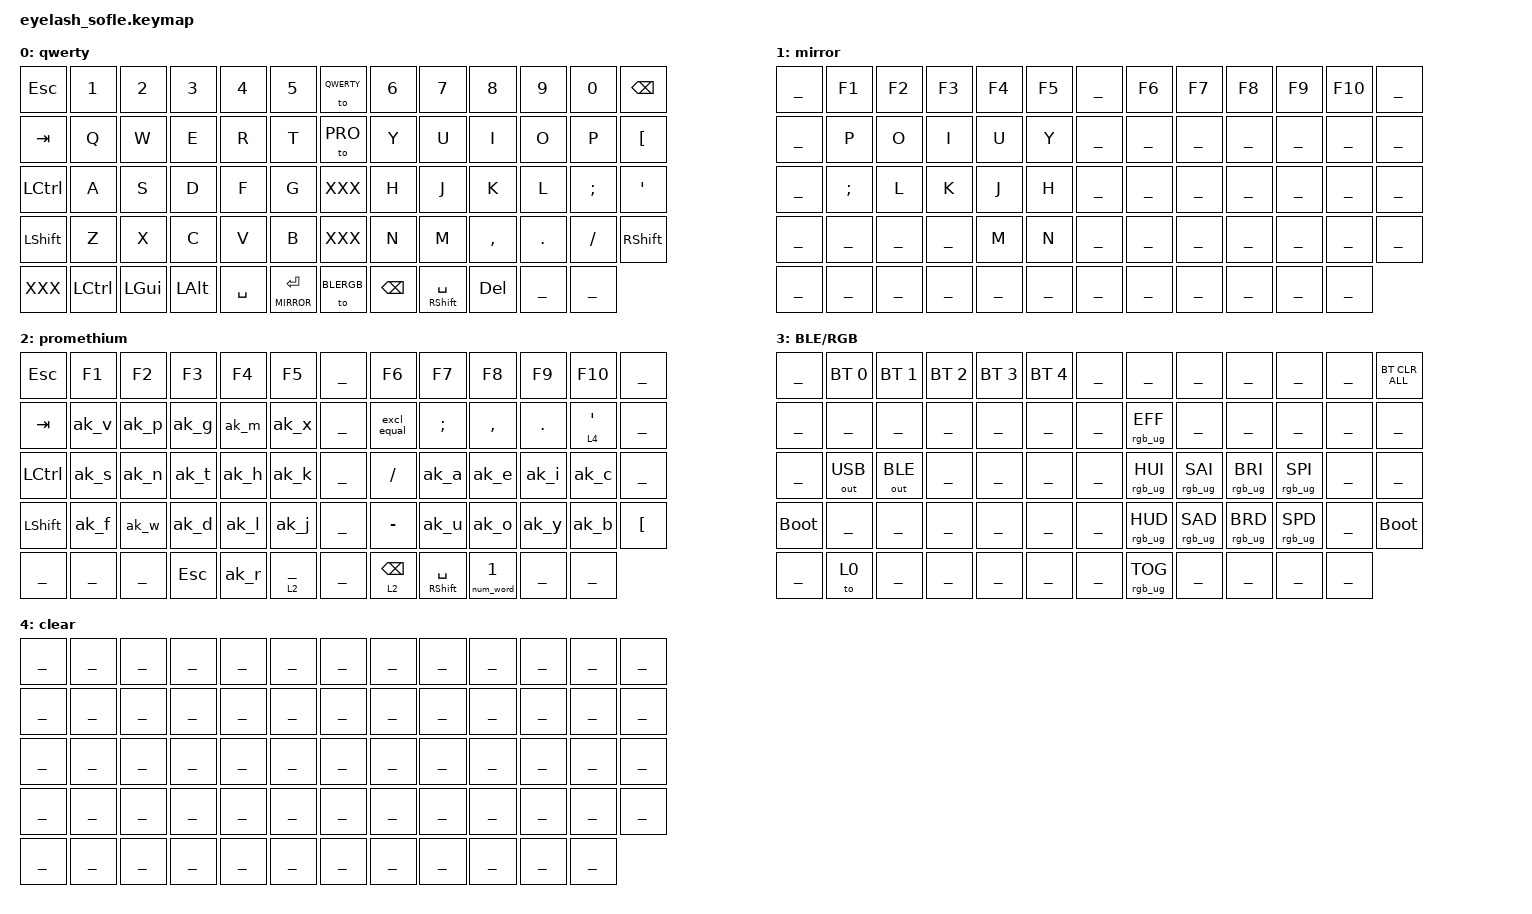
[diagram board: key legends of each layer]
#define ZMK_POINTING_DEFAULT_MOVE_VAL 1200  // 600
#define ZMK_POINTING_DEFAULT_SCRL_VAL 25   // 10

#define LEFT_HAND_KEYS 0 1 2 3 4 5 13 14 15 16 17 18 26 27 28 29 30 31 39 40 41 42 43 44 52 53 54 55 56 57
#define RIGHT_HAND_KEYS 7 8 9 10 11 12 20 21 22 23 24 25 33 34 35 36 37 38 46 47 48 49 50 51 59 60 61 62 63
#define LEFT_LEFT_COLUMN 0 13 26 39
#define THUMBS 52 53 54 55 56 59 60 61 62 63

#define QWERTY 0
#define MIRROR 1
#define PRO 2
#define NAV 0
#define SYM 0
#define FUN 0
#define MISC 0

#include "eyelash_sofle_layout.h"
#include "bernelius/constants.dtsi"

#include <input/processors.dtsi>
#include <zephyr/dt-bindings/input/input-event-codes.h>
#include <behaviors.dtsi>
#include <dt-bindings/zmk/behaviors.h>
#include <dt-bindings/zmk/bt.h>
#include <dt-bindings/zmk/ext_power.h>
#include <dt-bindings/zmk/keys.h>
#include <dt-bindings/zmk/pointing.h>
#include <dt-bindings/zmk/rgb.h>
#include <dt-bindings/zmk/outputs.h>
#include <behaviors/num_word.dtsi>
/*

&mmv_input_listener { input-processors = <&zip_xy_scaler 2 1>; };

&msc_input_listener { input-processors = <&zip_scroll_scaler 2 1>; };

&msc {
    acceleration-exponent = <1>;      // 0
    time-to-max-speed-ms = <100>;       // 300
    delay-ms = <0>;                   // 0
};

&mmv {
    time-to-max-speed-ms = <500>;
    acceleration-exponent = <1>;
    trigger-period-ms = <16>;
};

*/
/ {
    behaviors {
      #include "bernelius/pm_adaptive_keys.dtsi"
      #include "bernelius/behaviors.dtsi"
    };

    combos {
      #include "bernelius/combos.dtsi"
    };

    macros {
        #include "bernelius/macros.dtsi"
    };

    //left-most key on lower row is for an encoder (not currently present on board)


    #define QWERTY 0
    #define MIRROR 1
    #define BLERGB 3
    keymap {
        compatible = "zmk,keymap";

       

        layer_0 {
            display-name = "qwerty";
            bindings = <
//╭───────────────┬───────────────┬───────────────┬───────────────┬────────────────┬───────────────╮                   ╭────────────────┬───────────────┬───────────────┬───────────────┬───────────────┬───────────────╮
   &kp ESC         &kp N1          &kp N2          &kp N3          &kp N4           &kp N5            &to QWERTY        &kp N6           &kp N7          &kp N8          &kp N9          &kp N0          &kp BACKSPACE
//├───────────────┼───────────────┼───────────────┼───────────────┼────────────────┼───────────────┤                   ├────────────────┼───────────────┼───────────────┼───────────────┼───────────────┼───────────────┤
   &kp TAB         &kp Q           &kp W           &kp E           &kp R            &kp T             &to PRO           &kp Y            &kp U           &kp I           &kp O           &kp P           &kp LBKT
//├───────────────┼───────────────┼───────────────┼───────────────┼────────────────┼───────────────┤                   ├────────────────┼───────────────┼───────────────┼───────────────┼───────────────┼───────────────┤
   &kp LCTRL       &kp A           &kp S           &kp D           &kp F            &kp G             XXX               &kp H            &kp J           &kp K           &kp L           &kp SEMI        &kp APOS
//├───────────────┼───────────────┼───────────────┼───────────────┼────────────────┼───────────────┤                   ├────────────────┼───────────────┼───────────────┼───────────────┼───────────────┼───────────────┤ 
   &kp LSHFT       &kp Z           &kp X           &kp C           &kp V            &kp B             XXX               &kp N            &kp M           &kp COMMA       &kp DOT         &kp SLASH       &kp RSHIFT
//╰───────────────┼───────────────┼───────────────┼───────────────┼────────────────┼───────────────┤                   ├────────────────┼───────────────┼───────────────┼───────────────┼───────────────┼───────────────╯ 
   XXX             &kp LCTRL       &kp LGUI        &kp LALT        &kp SPACE        &lt MIRROR ENTER  &to BLERGB        &kp BACKSPACE    &mt RSHIFT SPACE &kp DELETE      ___             ___   
//                ╰───────────────┴───────────────┴───────────────┴────────────────┴───────────────╯                   ╰────────────────┴───────────────┴───────────────┴───────────────┴───────────────╯
            >;
        };

         layer_1 {
            display-name = "mirror";
            bindings = <
//╭───────────────┬───────────────┬───────────────┬───────────────┬───────────────┬───────────────╮                   ╭───────────────┬───────────────┬───────────────┬───────────────┬───────────────┬───────────────╮
   ___             &kp F1          &kp F2          &kp F3          &kp F4          &kp F5            ___ /* UP */      &kp F6          &kp F7          &kp F8          &kp F9          &kp F10         ___   
//├───────────────┼───────────────┼───────────────┼───────────────┼───────────────┼───────────────┤                   ├───────────────┼───────────────┼───────────────┼───────────────┼───────────────┼───────────────┤
   ___             &kp P           &kp O           &kp I           &kp U           &kp Y             ___ /* DOWN */    ___             ___             ___             ___             ___             ___   
//├───────────────┼───────────────┼───────────────┼───────────────┼───────────────┼───────────────┤                   ├───────────────┼───────────────┼───────────────┼───────────────┼───────────────┼───────────────┤
   ___             &kp SEMI        &kp L           &kp K           &kp J           &kp H             ___ /* LEFT */    ___             ___             ___             ___             ___             ___   
//├───────────────┼───────────────┼───────────────┼───────────────┼───────────────┼───────────────┤                   ├───────────────┼───────────────┼───────────────┼───────────────┼───────────────┼───────────────┤
   ___             ___             ___             ___             &kp M           &kp N             ___ /* RIGHT */   ___             ___             ___             ___             ___             ___   
//╰───────────────┼───────────────┼───────────────┼───────────────┼───────────────┼───────────────┤                   ├───────────────┼───────────────┼───────────────┼───────────────┼───────────────┼───────────────╯ 
   ___             ___             ___             ___             ___             ___               ___               ___             ___             ___             ___             ___   
//                ╰───────────────┴───────────────┴───────────────┴───────────────┴───────────────╯                   ╰───────────────┴───────────────┴───────────────┴───────────────┴───────────────╯
            >;
        }; 

        layer_2 {
            display-name = "promethium";
            bindings = <
//╭───────0───────┬───────1───────┬───────2───────┬────────3──────┬───────4───────┬───────5───────╮         6         ╭────────7──────┬───────8───────┬───────9───────┬───────10──────┬───────11──────┬───────12──────╮
   &kp ESC         &kp F1          &kp F2          &kp F3          &kp F4          &kp F5            ___               &kp F6          &kp F7          &kp F8          &kp F9          &kp F10         ___   
//├───────13──────┼───────14──────┼───────15──────┼───────16──────┼───────17──────┼───────18──────┤        19         ├───────20──────┼───────21──────┼───────22──────┼───────23──────┼───────24──────┼───────25──────┤
   &kp TAB         &ak_v           &ak_p           &ak_g           &ak_m           &ak_x             ___               &excl_equal     &kp SEMI        &kp COMMA       &kp DOT         &lt 4 APOS      ___ 
//├───────26──────┼───────27──────┼───────28──────┼───────29──────┼───────30──────┼───────31──────┤        32         ├───────33──────┼───────34──────┼───────35──────┼───────36──────┼───────37──────┼───────38──────┤
   &kp LCTRL       &ak_s           &ak_n           &ak_t           &ak_h           &ak_k             ___               &kp SLASH       &ak_a           &ak_e           &ak_i           &ak_c           ___
//├───────39──────┼───────40──────┼───────41──────┼───────42──────┼───────43──────┼───────44──────┤        45         ├───────46──────┼───────47──────┼───────48──────┼───────49──────┼───────50──────┼───────51──────┤
   &kp LSHIFT      &ak_f           &ak_w           &ak_d           &ak_l           &ak_j             ___               &kp MINUS       &ak_u           &ak_o           &ak_y           &ak_b           &kp LBKT
//╰───────52──────┼───────53──────┼───────54──────┼───────55──────┼───────56──────┼───────57──────┤        58         ├───────59──────┼───────60──────┼───────61──────┼───────62──────┼───────63──────┼───────────────╯ 
   ___             ___             ___             &kp ESCAPE      &ak_r           &lt 2 UNDER       ___               &lt 2 BSPC      &mt RSHFT SPACE &num_word 1     ___             ___   
//                ╰───────────────┴───────────────┴───────────────┴───────────────┴───────────────╯                   ╰───────────────┴───────────────┴───────────────┴───────────────┴───────────────╯
            >;
        };
        
        layer_3 {
            display-name = "BLE/RGB";
            bindings = <
//╭───────────────┬───────────────┬───────────────┬───────────────┬───────────────┬───────────────╮                   ╭───────────────┬───────────────┬───────────────┬───────────────┬───────────────┬───────────────╮
   ___             &bt BT_SEL 0    &bt BT_SEL 1    &bt BT_SEL 2    &bt BT_SEL 3    &bt BT_SEL 4      ___               ___             ___             ___             ___             ___             &bt BT_CLR_ALL
//├───────────────┼───────────────┼───────────────┼───────────────┼───────────────┼───────────────┤                   ├───────────────┼───────────────┼───────────────┼───────────────┼───────────────┼───────────────┤
   ___             ___             ___             ___             ___             ___               ___               &rgb_ug RGB_EFF ___             ___             ___             ___             ___   
//├───────────────┼───────────────┼───────────────┼───────────────┼───────────────┼───────────────┤                   ├───────────────┼───────────────┼───────────────┼───────────────┼───────────────┼───────────────┤
   ___             &out OUT_USB    &out OUT_BLE    ___             ___             ___               ___               &rgb_ug RGB_HUI &rgb_ug RGB_SAI &rgb_ug RGB_BRI &rgb_ug RGB_SPI ___             ___   
//├───────────────┼───────────────┼───────────────┼───────────────┼───────────────┼───────────────┤                   ├───────────────┼───────────────┼───────────────┼───────────────┼───────────────┼───────────────┤
   &bootloader     ___             ___             ___             ___             ___               ___               &rgb_ug RGB_HUD &rgb_ug RGB_SAD &rgb_ug RGB_BRD &rgb_ug RGB_SPD ___             &bootloader
//╰───────────────┼───────────────┼───────────────┼───────────────┼───────────────┼───────────────┤                   ├───────────────┼───────────────┼───────────────┼───────────────┼───────────────┼───────────────╯ 
   ___             &to 0           ___             ___             ___             ___               ___               &rgb_ug RGB_TOG ___             ___             ___             ___   
//                ╰───────────────┴───────────────┴───────────────┴───────────────┴───────────────╯                   ╰───────────────┴───────────────┴───────────────┴───────────────┴───────────────╯
            >;
        };

        layer_4 {
            display-name = "clear";
            bindings = <
//╭───────────────┬───────────────┬───────────────┬───────────────┬───────────────┬───────────────╮                   ╭───────────────┬───────────────┬───────────────┬───────────────┬───────────────┬───────────────╮
   ___             ___             ___             ___             ___             ___               ___               ___             ___             ___             ___             ___             ___   
//├───────────────┼───────────────┼───────────────┼───────────────┼───────────────┼───────────────┤                   ├───────────────┼───────────────┼───────────────┼───────────────┼───────────────┼───────────────┤
   ___             ___             ___             ___             ___             ___               ___               ___             ___             ___             ___             ___             ___   
//├───────────────┼───────────────┼───────────────┼───────────────┼───────────────┼───────────────┤                   ├───────────────┼───────────────┼───────────────┼───────────────┼───────────────┼───────────────┤
   ___             ___             ___             ___             ___             ___               ___               ___             ___             ___             ___             ___             ___   
//├───────────────┼───────────────┼───────────────┼───────────────┼───────────────┼───────────────┤                   ├───────────────┼───────────────┼───────────────┼───────────────┼───────────────┼───────────────┤
   ___             ___             ___             ___             ___             ___               ___               ___             ___             ___             ___             ___             ___   
//╰───────────────┼───────────────┼───────────────┼───────────────┼───────────────┼───────────────┤                   ├───────────────┼───────────────┼───────────────┼───────────────┼───────────────┼───────────────╯ 
   ___             ___             ___             ___             ___             ___               ___               ___             ___             ___             ___             ___   
//                ╰───────────────┴───────────────┴───────────────┴───────────────┴───────────────╯                   ╰───────────────┴───────────────┴───────────────┴───────────────┴───────────────╯
            >;
        };
    };
};
